# ESP32-C6 register map
Vendor: ESPRESSIF SYSTEMS (SHANGHAI) CO., LTD.; Series: ESP32 C-Series; File version: 2
CPU: RV32IMC r0p0, little endian, no MPU, no FPU, 4 interrupt priority bits
Address unit: 32 bits
Registers are 32-bit, read-write, reset 0x0 unless marked. A register's access mark holds for its fields unless they carry their own. Offsets are from the block's base; [hi:lo] are bit positions; {n}, {i} and the like mark numbered series.

## UHCI0 — Universal Host Controller Interface
Base 0x60005000
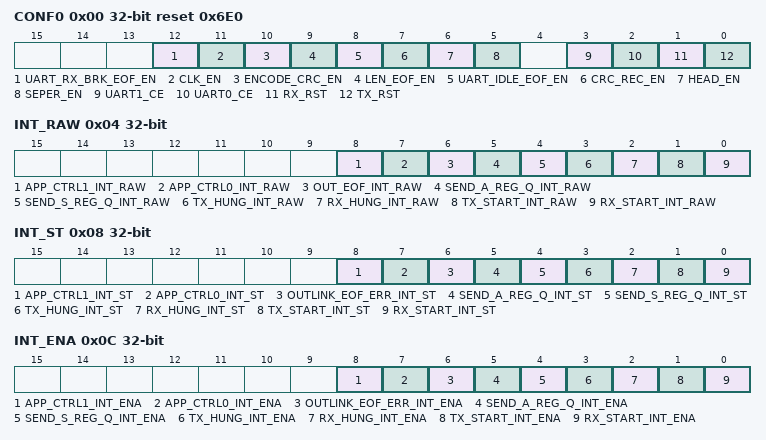
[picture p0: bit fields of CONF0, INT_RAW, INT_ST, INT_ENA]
0x00 CONF0 reset 0x6E0 — UHCI Configuration Register0
  [12] UART_RX_BRK_EOF_EN — If this bit is set to 1 UHCI will end payload receive process when NULL frame is received by UART.
  [11] CLK_EN — 1'b1: Force clock on for register. 1'b0: Support clock only when application writes registers.
  [10] ENCODE_CRC_EN — Set this bit to enable data integrity checking by appending a 16 bit CCITT-CRC to end of the payload.
  [9] LEN_EOF_EN — If this bit is set to 1 UHCI decoder receiving payload data is end when the receiving byte count has reached the specified value. The value is payload length indicated by UHCI packet header when UHCI_HEAD_EN is 1 or the value is configuration value when UHCI_HEAD_EN is 0. If this bit is set to 0 UHCI decoder receiving payload data is end when 0xc0 is received.
  [8] UART_IDLE_EOF_EN — If this bit is set to 1 UHCI will end the payload receiving process when UART has been in idle state.
  [7] CRC_REC_EN — Set this bit to enable UHCI to receive the 16 bit CRC.
  [6] HEAD_EN — Set this bit to encode the data packet with a formatting header.
  [5] SEPER_EN — Set this bit to separate the data frame using a special char.
  [3] UART1_CE — Set this bit to link up HCI and UART1.
  [2] UART0_CE — Set this bit to link up HCI and UART0.
  [1] RX_RST — Write 1 then write 0 to this bit to reset encode state machine.
  [0] TX_RST — Write 1 then write 0 to this bit to reset decode state machine.
0x04 INT_RAW access per field — UHCI Interrupt Raw Register
  [8] APP_CTRL1_INT_RAW rw — Indicates the raw interrupt of UHCI_APP_CTRL1_INT. Interrupt will be triggered when UHCI_APP_CTRL1_IN_SET is set to 1.
  [7] APP_CTRL0_INT_RAW rw — Indicates the raw interrupt of UHCI_APP_CTRL0_INT. Interrupt will be triggered when UHCI_APP_CTRL0_IN_SET is set to 1.
  [6] OUT_EOF_INT_RAW ro — Indicates the raw interrupt of UHCI_OUT_EOF_INT. Interrupt will be triggered when there are errors in EOF.
  [5] SEND_A_REG_Q_INT_RAW ro — Indicates the raw interrupt of UHCI_SEND_A_REG_Q_INT. Interrupt will be triggered when UHCI sends short packet successfully with always_send mode.
  [4] SEND_S_REG_Q_INT_RAW ro — Indicates the raw interrupt of UHCI_SEND_S_REG_Q_INT. Interrupt will be triggered when UHCI sends short packet successfully with single_send mode.
  [3] TX_HUNG_INT_RAW ro — Indicates the raw interrupt of UHCI_TX_HUNG_INT. Interrupt will be triggered when the required time of DMA reading RAM data exceeds the configuration value.
  [2] RX_HUNG_INT_RAW ro — Indicates the raw interrupt of UHCI_RX_HUNG_INT. Interrupt will be triggered when the required time of DMA receiving data exceeds the configuration value.
  [1] TX_START_INT_RAW ro — Indicates the raw interrupt of UHCI_TX_START_INT. Interrupt will be triggered when DMA detects delimiter.
  [0] RX_START_INT_RAW ro — Indicates the raw interrupt of UHCI_RX_START_INT. Interrupt will be triggered when delimiter is sent successfully.
0x08 INT_ST ro — UHCI Interrupt Status Register
  [8] APP_CTRL1_INT_ST — Indicates the interrupt status of UHCI_APP_CTRL1_INT.
  [7] APP_CTRL0_INT_ST — Indicates the interrupt status of UHCI_APP_CTRL0_INT.
  [6] OUTLINK_EOF_ERR_INT_ST — Indicates the interrupt status of UHCI_OUT_EOF_INT.
  [5] SEND_A_REG_Q_INT_ST — Indicates the interrupt status of UHCI_SEND_A_REG_Q_INT.
  [4] SEND_S_REG_Q_INT_ST — Indicates the interrupt status of UHCI_SEND_S_REG_Q_INT.
  [3] TX_HUNG_INT_ST — Indicates the interrupt status of UHCI_TX_HUNG_INT.
  [2] RX_HUNG_INT_ST — Indicates the interrupt status of UHCI_RX_HUNG_INT.
  [1] TX_START_INT_ST — Indicates the interrupt status of UHCI_TX_START_INT.
  [0] RX_START_INT_ST — Indicates the interrupt status of UHCI_RX_START_INT.
0x0C INT_ENA — UHCI Interrupt Enable Register
  [8] APP_CTRL1_INT_ENA — Set this bit to enable the interrupt of UHCI_APP_CTRL1_INT.
  [7] APP_CTRL0_INT_ENA — Set this bit to enable the interrupt of UHCI_APP_CTRL0_INT.
  [6] OUTLINK_EOF_ERR_INT_ENA — Set this bit to enable the interrupt of UHCI_OUT_EOF_INT.
  [5] SEND_A_REG_Q_INT_ENA — Set this bit to enable the interrupt of UHCI_SEND_A_REG_Q_INT.
  [4] SEND_S_REG_Q_INT_ENA — Set this bit to enable the interrupt of UHCI_SEND_S_REG_Q_INT.
  [3] TX_HUNG_INT_ENA — Set this bit to enable the interrupt of UHCI_TX_HUNG_INT.
  [2] RX_HUNG_INT_ENA — Set this bit to enable the interrupt of UHCI_RX_HUNG_INT.
  [1] TX_START_INT_ENA — Set this bit to enable the interrupt of UHCI_TX_START_INT.
  [0] RX_START_INT_ENA — Set this bit to enable the interrupt of UHCI_RX_START_INT.
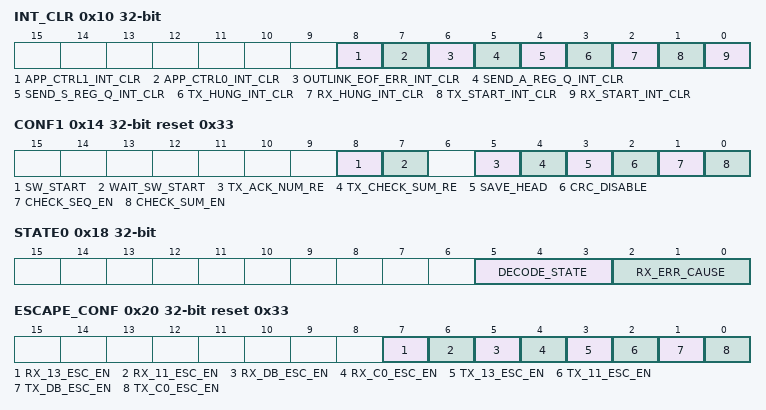
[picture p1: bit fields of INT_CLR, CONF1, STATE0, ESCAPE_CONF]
0x10 INT_CLR wo — UHCI Interrupt Clear Register
  [8] APP_CTRL1_INT_CLR — Set this bit to clear the raw interrupt of UHCI_APP_CTRL1_INT.
  [7] APP_CTRL0_INT_CLR — Set this bit to clear the raw interrupt of UHCI_APP_CTRL0_INT.
  [6] OUTLINK_EOF_ERR_INT_CLR — Set this bit to clear the raw interrupt of UHCI_OUT_EOF_INT.
  [5] SEND_A_REG_Q_INT_CLR — Set this bit to clear the raw interrupt of UHCI_SEND_A_REG_Q_INT.
  [4] SEND_S_REG_Q_INT_CLR — Set this bit to clear the raw interrupt of UHCI_SEND_S_REG_Q_INT.
  [3] TX_HUNG_INT_CLR — Set this bit to clear the raw interrupt of UHCI_TX_HUNG_INT.
  [2] RX_HUNG_INT_CLR — Set this bit to clear the raw interrupt of UHCI_RX_HUNG_INT.
  [1] TX_START_INT_CLR — Set this bit to clear the raw interrupt of UHCI_TX_START_INT.
  [0] RX_START_INT_CLR — Set this bit to clear the raw interrupt of UHCI_RX_START_INT.
0x14 CONF1 access per field reset 0x33 — UHCI Configuration Register1
  [8] SW_START wo — Set this bit to transmit data packet if UCHI_ENCODE_STATE is ST_SW_WAIT.
  [7] WAIT_SW_START rw — Set this bit to enable UHCI encoder transfer to ST_SW_WAIT status.
  [5] TX_ACK_NUM_RE rw — Set this bit to encode data packet with ACK when reliable data packet is ready.
  [4] TX_CHECK_SUM_RE rw — Set this bit to encode data packet with checksum.
  [3] SAVE_HEAD rw — Set this bit to save data packet head when UHCI receive data.
  [2] CRC_DISABLE rw — Set this bit to support CRC calculation, and data integrity check bit should 1.
  [1] CHECK_SEQ_EN rw — Set this bit to enable sequence number check when receiving.
  [0] CHECK_SUM_EN rw — Set this bit to enable head checksum check when receiving.
0x18 STATE0 ro — UHCI Receive Status Register
  [5:3] DECODE_STATE — Indicates UHCI decoder status.
  [2:0] RX_ERR_CAUSE — Indicates the error types when DMA receives the error frame. 3'b001: UHCI packet checksum error. 3'b010: UHCI packet sequence number error. 3'b011: UHCI packet CRC bit error. 3'b100: find 0xC0, but received packet is uncompleted. 3'b101: 0xC0 is not found, but received packet is completed. 3'b110: CRC check error.
0x1C STATE1 ro — UHCI Transmit Status Register
  [2:0] ENCODE_STATE — Indicates UHCI encoder status.
0x20 ESCAPE_CONF reset 0x33 — UHCI Escapes Configuration Register0
  [7] RX_13_ESC_EN — Set this bit to enable replacing 0x13 with special char when DMA receiving data.
  [6] RX_11_ESC_EN — Set this bit to enable replacing 0x11 with special char when DMA receiving data.
  [5] RX_DB_ESC_EN — Set this bit to enable replacing 0xDB with special char when DMA receiving data.
  [4] RX_C0_ESC_EN — Set this bit to enable replacing 0xC0 with special char when DMA receiving data.
  [3] TX_13_ESC_EN — Set this bit to enable resolve flow control char 0x13 when DMA receiving data.
  [2] TX_11_ESC_EN — Set this bit to enable resolve flow control char 0x11 when DMA receiving data.
  [1] TX_DB_ESC_EN — Set this bit to enable resolve char 0xDB when DMA receiving data.
  [0] TX_C0_ESC_EN — Set this bit to enable resolve char 0xC0 when DMA receiving data.
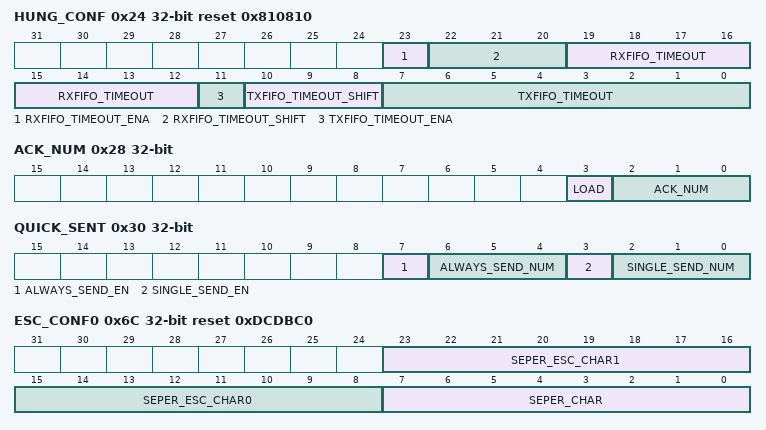
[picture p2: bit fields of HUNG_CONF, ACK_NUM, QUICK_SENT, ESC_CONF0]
0x24 HUNG_CONF reset 0x810810 — UHCI Hung Configuration Register0
  [23] RXFIFO_TIMEOUT_ENA — Set this bit to enable TX FIFO timeout when DMA sending data.
  [22:20] RXFIFO_TIMEOUT_SHIFT — Configures the maximum counter value.
  [19:12] RXFIFO_TIMEOUT — Stores the timeout value. DMA generates UHCI_TX_HUNG_INT for timeout when reading RAM data.
  [11] TXFIFO_TIMEOUT_ENA — Set this bit to enable TX FIFO timeout when receiving.
  [10:8] TXFIFO_TIMEOUT_SHIFT — Configures the maximum counter value.
  [7:0] TXFIFO_TIMEOUT — Stores the timeout value. DMA generates UHCI_TX_HUNG_INT for timeout when receiving data.
0x28 ACK_NUM access per field — UHCI Ack Value Configuration Register0
  [3] LOAD wo — Set this bit to load the ACK value of UHCI_ACK_NUM.
  [2:0] ACK_NUM rw — Indicates the ACK number during software flow control.
0x2C RX_HEAD ro — UHCI Head Register
  [31:0] RX_HEAD — Stores the head of received packet.
0x30 QUICK_SENT access per field — UCHI Quick send Register
  [7] ALWAYS_SEND_EN rw — Set this bit to enable sending short packet with always_send mode.
  [6:4] ALWAYS_SEND_NUM rw — Configures always_send mode.
  [3] SINGLE_SEND_EN wo — Set this bit to enable sending short packet with single_send mode.
  [2:0] SINGLE_SEND_NUM rw — Configures single_send mode.
{0x34+8i} REG_Q{i}_WORD0 (i=0..6) — UHCI Q{i}_WORD0 Quick Send Register
  [31:0] SEND_Q{i}_WORD0 — Serves as quick sending register in specified mode in UHCI_ALWAYS_SEND_NUM or UHCI_SINGLE_SEND_NUM.
{0x38+8i} REG_Q{i}_WORD1 (i=0..6) — UHCI Q{i}_WORD1 Quick Send Register
  [31:0] SEND_Q{i}_WORD1 — Serves as quick sending register in specified mode in UHCI_ALWAYS_SEND_NUM or UHCI_SINGLE_SEND_NUM.
0x6C ESC_CONF0 reset 0xDCDBC0 — UHCI Escapes Sequence Configuration Register0
  [23:16] SEPER_ESC_CHAR1 — Configures the second char of SLIP escape character, default value is 0xDC.
  [15:8] SEPER_ESC_CHAR0 — Configures the first char of SLIP escape character, default value is 0xDB.
  [7:0] SEPER_CHAR — Configures the delimiter for encoding, default value is 0xC0.
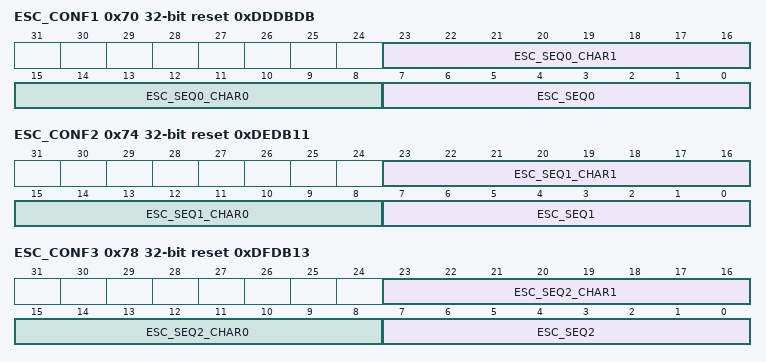
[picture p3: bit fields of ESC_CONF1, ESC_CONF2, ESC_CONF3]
0x70 ESC_CONF1 reset 0xDDDBDB — UHCI Escapes Sequence Configuration Register1
  [23:16] ESC_SEQ0_CHAR1 — Configures the second char of SLIP escape character, default value is 0xDD.
  [15:8] ESC_SEQ0_CHAR0 — Configures the first char of SLIP escape character, default value is 0xDB.
  [7:0] ESC_SEQ0 — Configures the char needing encoding, which is 0xDB as flow control char by default.
0x74 ESC_CONF2 reset 0xDEDB11 — UHCI Escapes Sequence Configuration Register2
  [23:16] ESC_SEQ1_CHAR1 — Configures the second char of SLIP escape character, default value is 0xDE.
  [15:8] ESC_SEQ1_CHAR0 — Configures the first char of SLIP escape character, default value is 0xDB.
  [7:0] ESC_SEQ1 — Configures the char needing encoding, which is 0x11 as flow control char by default.
0x78 ESC_CONF3 reset 0xDFDB13 — UHCI Escapes Sequence Configuration Register3
  [23:16] ESC_SEQ2_CHAR1 — Configures the second char of SLIP escape character, default value is 0xDF.
  [15:8] ESC_SEQ2_CHAR0 — Configures the first char of SLIP escape character, default value is 0xDB.
  [7:0] ESC_SEQ2 — Configures the char needing encoding, which is 0x13 as flow control char by default.
0x7C PKT_THRES reset 0x80 — UCHI Packet Length Configuration Register
  [12:0] PKT_THRS — Configures the data packet's maximum length when UHCI_HEAD_EN is 0.
0x80 DATE reset 0x2201100 — UHCI Version Register
  [31:0] DATE — Configures version.
